# TLE94x1 register map
Vendor: Infineon; File version: 0.2
Registers are 8-bit, read-write, no defined reset value unless marked. A register's access mark holds for its fields unless they carry their own. Offsets are from the block's base; [hi:lo] are bit positions; {n}, {i} and the like mark numbered series; 'fields as' and 'values as' point back to an identical list.

## CTRL — Control
Base 0x00000000
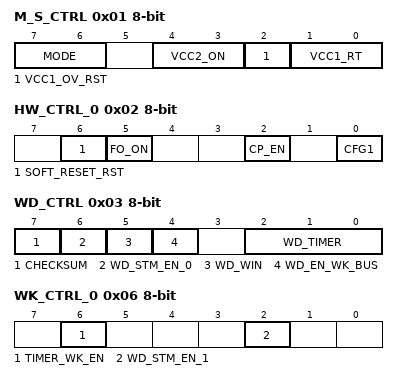
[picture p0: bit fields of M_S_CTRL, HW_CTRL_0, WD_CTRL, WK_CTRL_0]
0x01 M_S_CTRL — Mode- and Supply Control
  [7:6] MODE — SBC Mode Control
    0=Normal (SBC Normal Mode); 1=Sleep (SBC Sleep Mode); 2=Stop (SBC Stop Mode); 3=Soft_Reset (SBC Reset: Soft Reset is executed (configuration of RSTN triggering in bit SOFT_RESET_RST))
  [4:3] VCC2_ON — VCC2 Mode Control
    0=VCC2_off; 1=VCC2_on_in_Normal_Mode; 2=VCC2_on_in_Normal_and_Stop_Mode; 3=VCC2 always on (except in SBC Init - if not in SBC Development Mode, SBC Restart and Fail-Safe Mode)
  [2] VCC1_OV_RST — VCC1 Over Voltage leading to Restart / Fail-Safe Mode enable
    0=off (VCC1_ OV is set in case of VCC1_OV; no SBC Restart or Fail-Safe is entered for VCC1_OV); 1=activated (VCC1_ OV is set in case of VCC1_OV; depending on the device configuration SBC Restart or SBC Fail-Safe Mode is entered (see );)
  [1:0] VCC1_RT — VCC1 Reset Threshold Control
    0=Vrt1 selected (highest threshold); 1=Vrt2 selected; 2=Vrt3 selected; 3=Vrt4 selected
0x02 HW_CTRL_0 — Hardware Control 0
  [6] SOFT_RESET_RST — Soft Reset Configuration
    0=RSTN_triggered_by_Soft_Reset (RST will be triggered (pulled low) during a Soft Reset); 1=RSTN_not_triggered_by_Soft_Reset (no RST trigger during a Soft Reset)
  [5] FO_ON — Failure Output Activation
    0=off (FO not activated by software, FO will be activated by specified failures (see )); 1=on (FO activated by software (via SPI), only if configured as FO)
  [2] CP_EN — Charge Pump Output Enable
    0=off (Charge Pump is OFF); 1=on (Charge Pump Output is enabled)
  [0] CFG1 — Configuration Select 1 (see also )
    0=after_2nd (Depending on hardware configuration, SBC Restart or Fail-Safe Mode is reached after the 2. watchdog trigger failure (=default) - Config 3/4); 1=after_1st (Depending on hardware configuration, SBC Restart or Fail-Safe Mode is reached after the 1. watchdog trigger failure - Config 1/2)
0x03 WD_CTRL — Watchdog Control
  [7] CHECKSUM — Watchdog Setting Check Sum Bit
    0=Counts as 0 for checksum calculation; 1=Counts as 1 for checksum calculation
  [6] WD_STM_EN_0 — Watchdog Deactivation during Stop Mode, bit 0 ()
    0=active (Watchdog is active in Stop Mode); 1=off (Watchdog is deactivated in Stop Mode)
  [5] WD_WIN — Watchdog Type Selection
    0=Time-out (Watchdog works as a Time-Out watchdog); 1=Window (Watchdog works as a Window watchdog)
  [4] WD_EN_WK_BUS — Watchdog Enable after Bus (CAN) Wake in SBC Stop Mode
    0=off (Watchdog will not start after a CAN wake); 1=on (Watchdog starts with a long open window after CAN Wake)
  [2:0] WD_TIMER — Watchdog Timer Period
    0=10ms; 1=20ms; 2=50ms; 3=100ms; 4=200ms; 5=500ms; 6=1s (1000ms); 7=10s (10000ms)
0x04 BUS_CTRL_0 — Bus Control 0
  [2:0] CAN — HS-CAN Module Modes (CAN_2 is rw type)
    0=off (CAN OFF); 1=wake_capable (CAN is wake capable (no SWK)); 2=receive_only (CAN Receive Only Mode (no SWK)); 3=normal (CAN Normal Mode (no SWK)); 4=off (CAN OFF); 5=wake_capable_(SWK) (CAN is wake capable with SWK); 6=receive_only_(SWK) (CAN Receive Only Mode with SWK); 7=normal_(SWK) (CAN Normal Mode with SWK)
0x06 WK_CTRL_0 — Internal Wake Input Control
  [6] TIMER_WK_EN — Timer Wake Source Control (for cyclic wake)
    0=disabled (Timer wake disabled); 1=enabled (Timer is enabled as a wake source)
  [2] WD_STM_EN_1 — Watchdog Deactivation during Stop Mode, bit 1 ()
    0=WD_active_in_stop_mode (Watchdog is active in Stop Mode); 1=off (Watchdog is deactivated in Stop Mode)
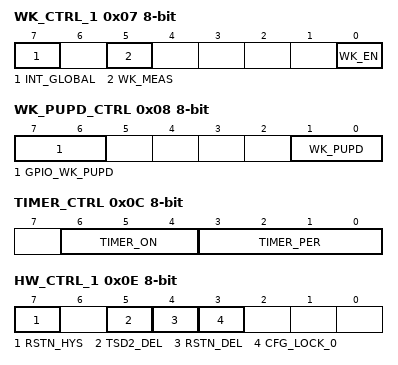
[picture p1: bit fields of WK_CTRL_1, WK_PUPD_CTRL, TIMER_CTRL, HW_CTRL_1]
0x07 WK_CTRL_1 — External Wake Source Control
  [7] INT_GLOBAL — Global Interrupt Configuration (see also )
    0=wake_only (Only wake sources trigger INTN (default)); 1=all_status_bits (All status information register bits will trigger INTN (including all wake sources))
  [5] WK_MEAS — Wake / Voltage Sensing Selection (see also )
    0=Wake functionality enabled for WK; 1=Voltage sensing functionality enabled, no wake-up events are generated
  [0] WK_EN — WK Wake Source Control
    0=disabled (WK wake disabled); 1=enabled (WK is enabled as a wake source)
0x08 WK_PUPD_CTRL — Wake Input Level Control
  [7:6] GPIO_WK_PUPD — GPIO WK Pull-Up / Pull-Down Configuration (only if GPIO configured as WK)
    0=none (No pull-up / pull-down selected); 1=Pull-down resistor selected; 2=Pull-up resistor selected; 3=Automatic switching to pull-up or pull-down
  [1:0] WK_PUPD — WK Pull-Up / Pull-Down Configuration
    values as GPIO_WK_PUPD
0x0B BUS_CTRL_3 — Bus Control 3
  [4] CAN_Flash — HS-CAN Flash Mode Activation
    0=disabled (Flash Mode disabled: CAN communication up to 5MBaud); 1=enabled (Flash Mode enabled: CAN communication for higher than 5MBaud (higher emission on CAN bus - no slew rate control))
0x0C TIMER_CTRL — Timer Control and Selection
  [6:4] TIMER_ON — Timer On-Time Configuration
    0=OFF / Low (timer not running, HSx output is low); 1=0.1ms on-time; 2=0.3ms on-time; 3=1.0ms on-time; 4=10ms on-time; 5=20ms on-time; 6=OFF / HIGH (timer not running, HSx output is high)
  [3:0] TIMER_PER — Timer Period Configuration
    0=10ms; 1=20ms; 2=50ms; 3=100ms; 4=200ms; 5=500ms; 6=1s; 7=2s; 8=5s; 9=10s; 10=20s; 11=50s; 12=100s; 13=200s; 14=500s; 15=1000s
0x0E HW_CTRL_1 — Hardware Control 1
  [7] RSTN_HYS — VCC1 Undervoltage Reset Hysteresis Selection (see also for more information)
    0=default hysteresis applies as specified in the electrical characteristics table; 1=Vrt1 (the highest rising threshold (Vrt1,r) is always used for the release of the undervoltage reset)
  [5] TSD2_DEL — TSD2 Minimum Waiting Time Selection
    0=1_s (Minimum waiting time until TSD2 is released again is always 1s); 1=extended (Minimum waiting time until TSD2 is released again is 1s, after >16 consecutive TSD2 events, it will be extended to x64)
  [4] RSTN_DEL — Reset Delay Time Selection
    0=standard (The extended reset delay time is selected (default)); 1=reduced (The reduced reset delay time is selected)
  [3] CFG_LOCK_0 — Configuration Lock Bit - Level 0
    0=un-locked (CP_EN and GPIO can be modified); 1=locked (CP_EN and GPIO is locked and cannot be modified)
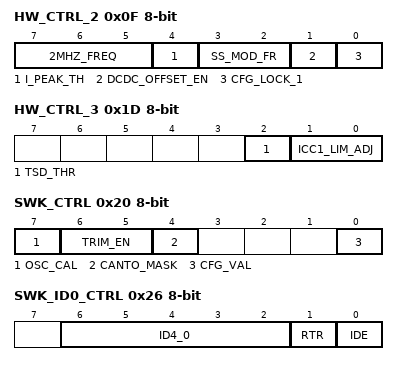
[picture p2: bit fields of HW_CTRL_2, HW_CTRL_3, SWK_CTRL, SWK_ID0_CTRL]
0x0F HW_CTRL_2 — Hardware Control 2
  [7:5] 2MHZ_FREQ — SMPS and Charge Pump Switching Frequency
    0=1.8MHz; 1=2.0MHz; 2=2.2MHz (default value); 3=2.4MHz; 4=450kHz (divider by 4 is active, switching frequency is 450kHz); 5=500kHz (divider by 4 is active, switching frequency is 500kHz); 6=550kHz (divider by 4 is active, switching frequency is 550kHz); 7=600kHz (divider by 4 is active, switching frequency is 600kHz)
  [4] I_PEAK_TH — VCC1 Active Peak Threshold Selection
    0=low (low VCC1 active peak threshold selected (ICC1,peak_1)); 1=high VCC1 active peak threshold selected (ICC1,peak_2)
  [3:2] SS_MOD_FR — Spread Spectrum Modulation Frequency Setting of integrated 2MHz oscillator for charge pump and SMPS regulator (Valid for 2MHz_FREQ = ‘001')(if low frequency range is selected, then only possible configuration is ‘11', other values can be selected but are ignored)
    0=disabled (Spread Spectrum disabled); 1=15.625kHz Modulation Frequency; 2=31.250kHz Modulation Frequency; 3=62.500kHz Modulation Frequency
  [1] DCDC_OFFSET_EN — SMPS Regulation Voltage in SBC Normal Mode for Loads below the Active Peak Threshold (Soft Reset Value = ‘0')
    0=off (No offset: VCC1 output is always regulated at the same voltage); 1=on (Offset activated: Only low-power regulator is active below the active peak threshold, i.e. same behavior as in SBC Stop Mode.)
  [0] CFG_LOCK_1 — Configuration Lock Bit - Level 1
    0=un-locked (Bits with bit type ‘rwl' (except CP_EN and GPIO) can be modified); 1=locked (Bits with bit type ‘rwl' (except CP_EN and GPIO) are locked and cannot be modified anymore until next device power-up.)
0x17 GPIO_CTRL — GPIO Configuration Control
  [2:0] GPIO — GPIO Configuration
    0=FO (FO selected (default)); 1=FO (FO selected); 2=FO (FO selected); 3=High-Side_Timer (High-Side controlled by TIMER (cyclic sense)); 4=off; 5=Wake input enabled (16us static filter); 6=Low-Side_PWM (Low-Side Switch controlled by PWM); 7=High-Side_PWM (High-Side Switch controlled by PWM)
0x18 PWM_CTRL — PWM Configuration Control
  [7:0] PWM_DC — PWM Duty Cycle Setting (bit0 = LSB; bit7 = MSB)
0x1C PWM_FREQ_CTRL — PWM Frequency Configuration Control
  [1:0] PWM_FREQ — Spread Spectrum Modulation Frequency Setting
    0=100Hz configuration; 1=200Hz configuration; 2=325Hz configuration; 3=400Hz configuration
0x1D HW_CTRL_3 — Hardware Control 3
  [2] TSD_THR — Thermal Shutdown Threshold (TSD1 & TSD2) Configuration
    0=Default shutdown threshold selected; 1=higher shutdown threshold selected
  [1:0] ICC1_LIM_ADJ — Configuration of ICC1 current limitation
    0=-25% (1 step down from default value (-25% of typ. default)); 1=default value (typ. 1000mA); 2=+20% (1 step up form default value (+20% of default)); 3=+50% (2 steps up from default value (+50% of default))
0x1E SYS_STATUS_CTRL_0 — System Status Control Low Byte
  [7:0] SYS_STAT_L — System Status Control Low Byte (bit0=LSB; bit7=MSB)
0x1F SYS_STATUS_CTRL_1 — System Status Control High Byte
  [7:0] SYS_STAT_H — System Status Control High Byte (bit8=LSB; bit15=MSB)
0x20 SWK_CTRL — CAN Selective Wake Control
  [7] OSC_CAL — Oscillator Calibration Mode
    0=disabled (Oscillator Calibration is disabled); 1=enabled (Oscillator Calibration is enabled)
  [6:5] TRIM_EN — (Un)locking mechanism of oscillator recalibration
    0=locked_0; 1=locked_1; 2=locked_2; 3=unlocked
  [4] CANTO_MASK — CAN Time Out Masking
    0=no_INTN (CAN time-out is masked - no interrupt (on pin INTN) is triggered); 1=INTN (CAN time-out is signaled on INTN)
  [0] CFG_VAL — SWK Configuration valid
    0=not_valid (Configuration is not valid (SWK not possible)); 1=valid (SWK configuration valid, needs to be set to enable SWK)
0x21 SWK_BTL0_CTRL — SWK Bit Timing Logic Control1
  [7:0] TBIT — Number of Time Quanta in a Bit Time
0x22 SWK_BTL1_CTRL — SWK Bit Timing Control2
  [5:0] SP — Sampling Point Position
0x23 SWK_ID3_CTRL — SWK WUF Identifier bits 28...21
  [7:0] ID28_21 — WUF Identifier Bits 28...21
0x24 SWK_ID2_CTRL — SWK WUF Identifier bits 20...13
  [7:0] ID20_13 — WUF Identifier Bits 20...13
0x25 SWK_ID1_CTRL — SWK WUF Identifier bits 12...5
  [7:0] ID12_5 — WUF Identifier Bits 12...5
0x26 SWK_ID0_CTRL — SWK WUF Identifier bits 4...0
  [6:2] ID4_0 — WUF Identifier Bits 4..0
  [1] RTR — Remote Transmission Request Field (acc. ISO 11898-1)
    0=disabled (Normal Data Frame); 1=enabled (Remote Transmission Request)
  [0] IDE — Identifier Extension Bit
    0=11bit (Standard Identifier Length (11 bit)); 1=29bit (Extended Identifier Length (29 bit))
0x27 SWK_MASK_ID3_CTRL — SWK WUF Identifier Mask bits 28...21
  [7:0] MASK_ID28_21 — WUF Identifier Mask Bits 28...21
    0=ignored (Unmasked - bit is ignored); 1=enabled (Masked - bit is compared in CAN frame)
0x28 SWK_MASK_ID2_CTRL — SWK WUF Identifier Mask bits 20...13
  [7:0] MASK_ID20_13 — WUF Identifier Mask Bits 20...13
    values as SWK_MASK_ID3_CTRL.MASK_ID28_21
0x29 SWK_MASK_ID1_CTRL — SWK WUF Identifier Mask bits 12...5
  [7:0] MASK_ID12_5 — WUF Identifier Mask Bits 12...5
    values as SWK_MASK_ID3_CTRL.MASK_ID28_21
0x2A SWK_MASK_ID0_CTRL — SWK WUF Identifier bits 4...0
  [6:2] MASK_ID4_0 — WUF Identifier MASK Bits 4..0
    0=irgnored (Unmasked - bit is ignored); 1=enabled (Masked - bit is compared in CAN frame)
0x2B SWK_DLC_CTRL — SWK Frame Data Length Code Control
  [3:0] DLC — Payload length in number of bytes
    0=Frame Data Length = 0 or cleared; {v}=Frame Data Length = {v} (v=1..8)
0x2C SWK_DATA7_CTRL — SWK Data7 Register
  [7:0] DATA7 — Data7 byte content(bit0=LSB; bit7=MSB)
0x2D SWK_DATA6_CTRL — SWK Data6 Register
  [7:0] DATA6 — Data6 byte content (bit0=LSB; bit7=MSB)
0x2E SWK_DATA5_CTRL — SWK Data5 Register
  [7:0] DATA5 — Data5 byte content (bit0=LSB; bit7=MSB)
0x2F SWK_DATA4_CTRL — SWK Data4 Register
  [7:0] DATA4 — Data4 byte content (bit0=LSB; bit7=MSB)
0x30 SWK_DATA3_CTRL — SWK Data3 Register
  [7:0] DATA3 — Data3 byte content (bit0=LSB; bit7=MSB)
0x31 SWK_DATA2_CTRL — SWK Data2 Register
  [7:0] DATA2 — Data2 byte content (bit0=LSB; bit7=MSB)
0x32 SWK_DATA1_CTRL — SWK Data1 Register
  [7:0] DATA1 — Data1 byte content (bit0=LSB; bit7=MSB)
0x33 SWK_DATA0_CTRL — SWK Data0 Register
  [7:0] DATA0 — Data0 byte content (bit0=LSB; bit7=MSB)
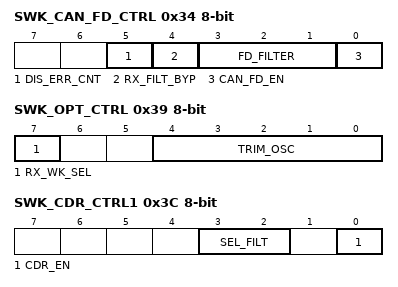
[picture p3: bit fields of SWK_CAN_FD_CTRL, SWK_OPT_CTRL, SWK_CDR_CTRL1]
0x34 SWK_CAN_FD_CTRL — CAN FD Configuration Control Register
  [5] DIS_ERR_CNT — Error Counter Disable Function
    0=counter_enabled (Error Counter is enabled during SWK); 1=counter_disabled (Error counter is disabled during SWK only if CAN_FD_EN = ‘1')
  [4] RX_FILT_BYP — RX Receiver Filter Bypass
    0=disabled (RX Filter not bypassed); 1=enabled (RX Filter bypassed)
  [3:1] FD_FILTER — CAN FD Dominant Filter Time
    0=50ns; 1=100ns; 2=150ns; 3=200ns; 4=250ns; 5=300ns; 6=350ns; 7=700ns
  [0] CAN_FD_EN — CAN FD Tolerant Mode
    0=disabled (CAN FD Tolerant Mode disabled); 1=enabled (CAN FD Tolerant Mode enabled)
0x38 SWK_OSC_TRIM_CTRL — SWK Oscillator Trimming Register
  [7:0] TRIM_OSC — Oscillator trimming (bit0=LSB; bit7=MSB); (only writable if TRIM_EN = ‘11')
0x39 SWK_OPT_CTRL — Selective Wake Options Register
  [7] RX_WK_SEL — SWK Receiver selection (only accessible if TRIM_EN = ‘11')
    0=Low-Power Receiver selected during SWK; 1=Standard Receiver selected during SWK
  [4:0] TRIM_OSC — Oscillator trimming (bit8=LSB; bit12=MSB); (only writable if TRIM_EN = ‘11')
0x3A SWK_OSC_CAL_H_STAT ro — SWK Oscillator Calibration High Register
  [7:0] OSC_CAL_H — Oscillator Calibration High Register
0x3B SWK_OSC_CAL_L_STAT ro — SWK Oscillator Calibration Low Register
  [7:0] OSC_CAL_L — Oscillator Calibration Low Register
0x3C SWK_CDR_CTRL1 — CDR Control 1 Register
  [3:2] SEL_FILT — Select Time Constant of Filter
    0=Time constant 8; 1=16(default) (Time constant 16 (default)); 2=Time constant 32; 3=adaptive (adapt distance between falling edges 2, 3 bit: Time constant 32 distance between f. edges 4, 5, 6, 7, 8 bit: Time constant 16 distance between falling edges 9, 10 bit: Time constant 8)
  [0] CDR_EN — Enable CDR
    0=disabled (CDR disabled); 1=enabled (CDR enabled)
0x3D SWK_CDR_CTRL2 — CDR Control 2Register
  [1:0] SEL_OSC_CLK — Input Frequency for CDR module
0x3E SWK_CDR_LIMIT_HIGH_CTRL — SWK CDR Upper Limit Control
  [7:0] CDR_LIM_H — Upper Bit Time Detection Range of Clock and Data Recovery
0x3F SWK_CDR_LIMIT_LOW_CTRL — SWK CDR Lower Limit Control
  [7:0] CDR_LIM_L — Lower Bit Time Detection Range of Clock and Data Recovery
